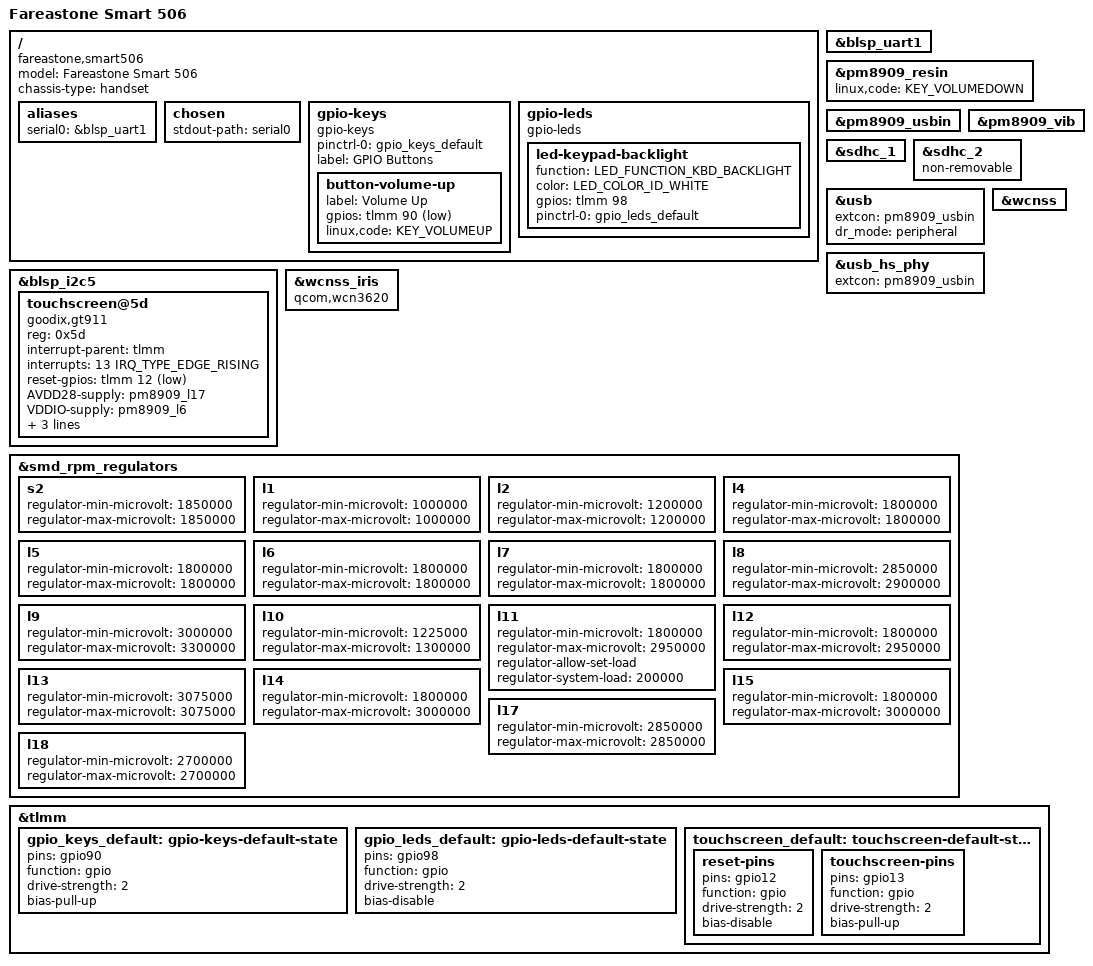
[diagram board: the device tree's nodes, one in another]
// SPDX-License-Identifier: GPL-2.0-only

/dts-v1/;

#include "qcom-msm8909-pm8909.dtsi"

#include <dt-bindings/gpio/gpio.h>
#include <dt-bindings/input/input.h>
#include <dt-bindings/interrupt-controller/irq.h>

/ {
	model = "Fareastone Smart 506";
	compatible = "fareastone,smart506", "qcom,msm8909";
	chassis-type = "handset";

	aliases {
		serial0 = &blsp_uart1;
	};

	chosen {
		stdout-path = "serial0";
	};

	gpio-keys {
		compatible = "gpio-keys";

		pinctrl-0 = <&gpio_keys_default>;
		pinctrl-names = "default";

		label = "GPIO Buttons";

		button-volume-up {
			label = "Volume Up";
			gpios = <&tlmm 90 GPIO_ACTIVE_LOW>;
			linux,code = <KEY_VOLUMEUP>;
		};
	};

	gpio-leds {
		compatible = "gpio-leds";

		led-keypad-backlight {
			function = LED_FUNCTION_KBD_BACKLIGHT;
			color = <LED_COLOR_ID_WHITE>;
			gpios = <&tlmm 98 GPIO_ACTIVE_HIGH>;

			pinctrl-0 = <&gpio_leds_default>;
			pinctrl-names = "default";
		};
	};
};

&blsp_i2c5 {
	status = "okay";

	touchscreen@5d {
		compatible = "goodix,gt911";
		reg = <0x5d>;

		interrupt-parent = <&tlmm>;
		interrupts = <13 IRQ_TYPE_EDGE_RISING>;

		reset-gpios = <&tlmm 12 GPIO_ACTIVE_LOW>;

		AVDD28-supply = <&pm8909_l17>;
		VDDIO-supply = <&pm8909_l6>;

		touchscreen-size-x = <720>;
		touchscreen-size-y = <1280>;

		pinctrl-0 = <&touchscreen_default>;
		pinctrl-names = "default";
	};
};

&blsp_uart1 {
	status = "okay";
};

&pm8909_resin {
	linux,code = <KEY_VOLUMEDOWN>;
	status = "okay";
};

&pm8909_usbin {
	status = "okay";
};

&pm8909_vib {
	status = "okay";
};

&sdhc_1 {
	status = "okay";
};

&sdhc_2 {
	non-removable;
	status = "okay";
};

&usb {
	extcon = <&pm8909_usbin>;
	dr_mode = "peripheral";
	status = "okay";
};

&usb_hs_phy {
	extcon = <&pm8909_usbin>;
};

&wcnss {
	status = "okay";
};

&wcnss_iris {
	compatible = "qcom,wcn3620";
};

&smd_rpm_regulators {
	s2 {
		regulator-min-microvolt = <1850000>;
		regulator-max-microvolt = <1850000>;
	};

	l1 {
		regulator-min-microvolt = <1000000>;
		regulator-max-microvolt = <1000000>;
	};

	l2 {
		regulator-min-microvolt = <1200000>;
		regulator-max-microvolt = <1200000>;
	};

	l4 {
		regulator-min-microvolt = <1800000>;
		regulator-max-microvolt = <1800000>;
	};

	l5 {
		regulator-min-microvolt = <1800000>;
		regulator-max-microvolt = <1800000>;
	};

	l6 {
		regulator-min-microvolt = <1800000>;
		regulator-max-microvolt = <1800000>;
	};

	l7 {
		regulator-min-microvolt = <1800000>;
		regulator-max-microvolt = <1800000>;
	};

	l8 {
		regulator-min-microvolt = <2850000>;
		regulator-max-microvolt = <2900000>;
	};

	l9 {
		regulator-min-microvolt = <3000000>;
		regulator-max-microvolt = <3300000>;
	};

	l10 {
		regulator-min-microvolt = <1225000>;
		regulator-max-microvolt = <1300000>;
	};

	l11 {
		regulator-min-microvolt = <1800000>;
		regulator-max-microvolt = <2950000>;
		regulator-allow-set-load;
		regulator-system-load = <200000>;
	};

	l12 {
		regulator-min-microvolt = <1800000>;
		regulator-max-microvolt = <2950000>;
	};

	l13 {
		regulator-min-microvolt = <3075000>;
		regulator-max-microvolt = <3075000>;
	};

	l14 {
		regulator-min-microvolt = <1800000>;
		regulator-max-microvolt = <3000000>;
	};

	l15 {
		regulator-min-microvolt = <1800000>;
		regulator-max-microvolt = <3000000>;
	};

	l17 {
		regulator-min-microvolt = <2850000>;
		regulator-max-microvolt = <2850000>;
	};

	l18 {
		regulator-min-microvolt = <2700000>;
		regulator-max-microvolt = <2700000>;
	};
};

&tlmm {
	gpio_keys_default: gpio-keys-default-state {
		pins = "gpio90";
		function = "gpio";
		drive-strength = <2>;
		bias-pull-up;
	};

	gpio_leds_default: gpio-leds-default-state {
		pins = "gpio98";
		function = "gpio";
		drive-strength = <2>;
		bias-disable;
	};

	touchscreen_default: touchscreen-default-state {
		reset-pins {
			pins = "gpio12";
			function = "gpio";
			drive-strength = <2>;
			bias-disable;
		};

		touchscreen-pins {
			pins = "gpio13";
			function = "gpio";
			drive-strength = <2>;
			bias-pull-up;
		};
	};
};
